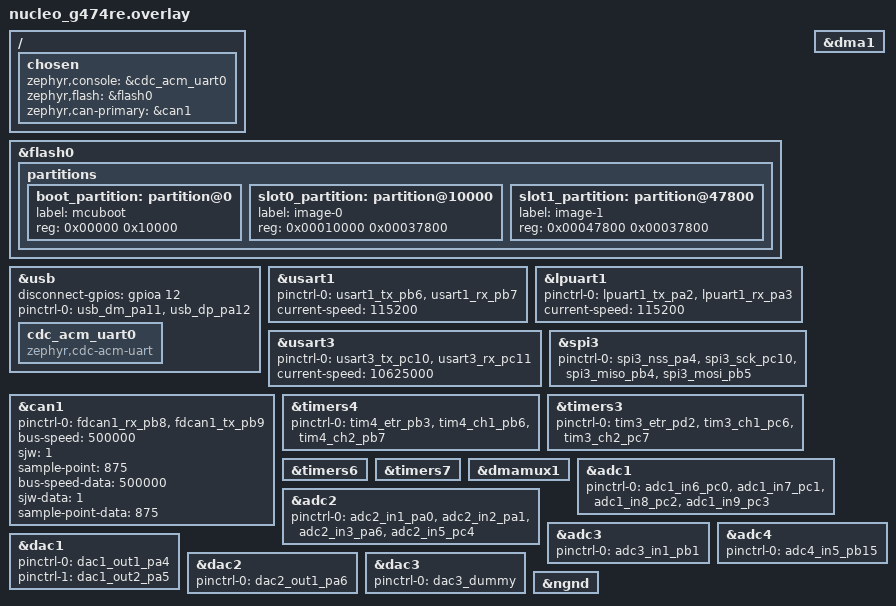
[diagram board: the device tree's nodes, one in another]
/*
 * Copyright (c) 2022-2024 OwnTech.
 *
 * SPDX-License-Identifier: LGPL-2.1
 */



// Board-related definitions
#include "pinctrl.dtsi"
#include "hrtim.dtsi"


/ {
	chosen {
		zephyr,console = &cdc_acm_uart0;
		zephyr,flash = &flash0;
		zephyr,can-primary = &can1;
	};
};


/***********/
/* Storage */
/***********/

&flash0 {
	/*
	 * For more information, see:
	 * http://docs.zephyrproject.org/latest/guides/dts/index.html#flash-partitions
	 */
	partitions {
		boot_partition: partition@0 {
			label = "mcuboot";
			reg = <0x00000 0x10000>;
		};

		slot0_partition: partition@10000 {
			label = "image-0";
			reg = <0x00010000 0x00037800>;
		};

		slot1_partition: partition@47800 {
			label = "image-1";
			reg = <0x00047800 0x00037800>;
		};
	};
};

/*********/
/* USB */
/*********/

&usb {
	disconnect-gpios = <&gpioa 12 GPIO_ACTIVE_HIGH>;
	status = "okay";
};

zephyr_udc0: &usb {
	pinctrl-0 = <&usb_dm_pa11 &usb_dp_pa12>;
	pinctrl-names = "default";
	status = "okay";
	cdc_acm_uart0: cdc_acm_uart0 {
		compatible = "zephyr,cdc-acm-uart";
	};
};

/*****************/
/* Communication */
/*****************/

// UART

&usart1 {
	pinctrl-0 = <&usart1_tx_pb6 &usart1_rx_pb7>;
	current-speed = <115200>;
	status = "okay";
};

&lpuart1 {
	pinctrl-0 = <&lpuart1_tx_pa2 &lpuart1_rx_pa3>;
	current-speed = <115200>;
	status = "okay";
};

&usart3 {
	pinctrl-0 = < &usart3_tx_pc10 &usart3_rx_pc11 >;
	pinctrl-names = "default";
	current-speed = < 10625000 >;
	status = "okay";
};

// SPI

&spi3 {
	pinctrl-0 = <&spi3_nss_pa4 &spi3_sck_pc10 &spi3_miso_pb4 &spi3_mosi_pb5>;
	status = "okay";
};

// CAN

&can1 {
	pinctrl-0 = <&fdcan1_rx_pb8 &fdcan1_tx_pb9>;
	bus-speed = <500000>;
	sjw = <1>;
	sample-point = <875>;
	bus-speed-data = <500000>;
	sjw-data = <1>;
	sample-point-data = <875>;
	status = "okay";
};

/*********/
/* Timer */
/*********/

&timers4 {
	pinctrl-names = "incremental_encoder";
	pinctrl-0 = <&tim4_etr_pb3 &tim4_ch1_pb6 &tim4_ch2_pb7 >;
	status = "okay";
};

&timers3 {
	pinctrl-names = "incremental_encoder";
	pinctrl-0 = <&tim3_etr_pd2 &tim3_ch1_pc6 &tim3_ch2_pc7>;
	status = "okay";
};


&timers6 {
	status = "okay";
};

&timers7 {
	status = "okay";
};

/*******/
/* DMA */
/*******/

&dma1 {
	status = "okay";
};

&dmamux1 {
	status = "okay";
};

/*******/
/* ADC */
/*******/

&adc1 {
	pinctrl-0 = <&adc1_in6_pc0 &adc1_in7_pc1 &adc1_in8_pc2 &adc1_in9_pc3>;
	pinctrl-names = "default";
	status = "okay";
};

&adc2 {
	pinctrl-0 = <&adc2_in1_pa0 &adc2_in2_pa1 &adc2_in3_pa6 &adc2_in5_pc4>;
	pinctrl-names = "default";
	status = "okay";
};

&adc3 {
	pinctrl-0 = <&adc3_in1_pb1>;
	pinctrl-names = "default";
	status = "okay";
};

&adc4 {
	pinctrl-0 = <&adc4_in5_pb15>;
	pinctrl-names = "default";
	status = "okay";
};

/*******/
/* DAC */
/*******/

&dac1 {
	pinctrl-0 = <&dac1_out1_pa4>;
	pinctrl-1 = <&dac1_out2_pa5>;
	pinctrl-names = "default", "secondary";
	status = "okay";
};

&dac2 {
	pinctrl-0 = <&dac2_out1_pa6 >;
	pinctrl-names = "default";
	status = "okay";
};

&dac3 {
	status = "okay";
	pinctrl-0 = <&dac3_dummy>;
	pinctrl-names = "phantom";
};

/********/
/* NGND */
/********/

&ngnd {
	status = "okay";
};
